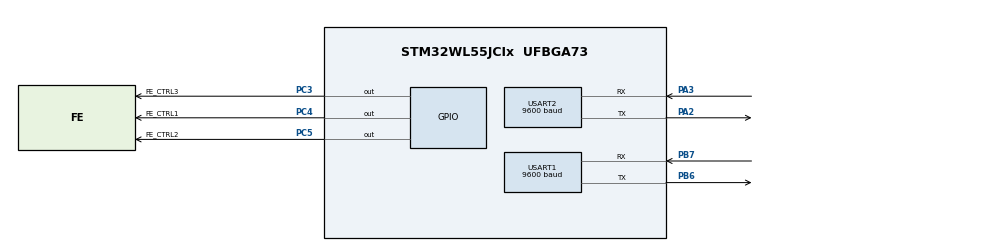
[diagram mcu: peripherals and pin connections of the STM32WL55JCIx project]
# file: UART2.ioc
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Mcu.Family=STM32WL
Mcu.Name=STM32WL55JCIx
Mcu.Package=UFBGA73
NUCLEO-WL55JC1.BUTTON=1
NUCLEO-WL55JC1.BUTTON2=1
NUCLEO-WL55JC1.BUTTON3=1
NUCLEO-WL55JC1.LD1=true
NUCLEO-WL55JC1.LD2=true
NUCLEO-WL55JC1.LD3=true
NUCLEO-WL55JC1.VCP=true
NVIC.EXTI0_IRQn=true\:0\:0\:false\:false\:true\:false\:true\:true
NVIC.EXTI1_IRQn=true\:0\:0\:false\:false\:true\:false\:true\:true
NVIC.EXTI9_5_IRQn=true\:0\:0\:false\:false\:true\:false\:true\:true
NVIC.PriorityGroup=NVIC_PRIORITYGROUP_4
NVIC.RCC_IRQn=true\:0\:0\:false\:false\:true\:true\:false\:true
PA2.Mode=Asynchronous
PA2.Signal=USART2_TX
PA3.Mode=Asynchronous
PA3.Signal=USART2_RX
PB6.Mode=Asynchronous
PB6.Signal=USART1_TX
PB7.Mode=Asynchronous
PB7.Signal=USART1_RX
PC14-OSC32_IN.GPIO_Label=RCC_OSC32_IN
PC14-OSC32_IN.Signal=RCC_OSC32_IN
PC15-OSC32_OUT.GPIO_Label=RCC_OSC32_OUT
PC15-OSC32_OUT.Signal=RCC_OSC32_OUT
PC3.GPIO_Label=FE_CTRL3
PC3.GPIO_Speed=GPIO_SPEED_FREQ_VERY_HIGH
PC3.Signal=GPIO_Output
PC4.GPIO_Label=FE_CTRL1
PC4.GPIO_Speed=GPIO_SPEED_FREQ_VERY_HIGH
PC4.Signal=GPIO_Output
PC5.GPIO_Label=FE_CTRL2
PC5.GPIO_Speed=GPIO_SPEED_FREQ_VERY_HIGH
PC5.Signal=GPIO_Output
ProjectManager.HeapSize=0x200
ProjectManager.StackSize=0x400
ProjectManager.TargetToolchain=STM32CubeIDE
RCC.HSE_VALUE=32000000
RCC.HSI_VALUE=16000000
RCC.LSE_VALUE=32768
RCC.VCOOutputFreq_Value=32000000
USART1.BaudRate=9600
USART1.VirtualMode-Asynchronous=VM_ASYNC
USART2.BaudRate=9600
USART2.VirtualMode-Asynchronous=VM_ASYNC
VP_NUCLEO-WL55JC1_VS_BSP_COMMON.Mode=COMMON
board=NUCLEO-WL55JC1

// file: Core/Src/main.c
/* USER CODE BEGIN Header */
/**
  ******************************************************************************
  * @file           : main.c
  * @brief          : Main program body
  ******************************************************************************
  * @attention
  *
  * Copyright (c) 2026 STMicroelectronics.
  * All rights reserved.
  *
  * This software is licensed under terms that can be found in the LICENSE file
  * in the root directory of this software component.
  * If no LICENSE file comes with this software, it is provided AS-IS.
  *
  ******************************************************************************
  */
/* USER CODE END Header */
#include "main.h"
#include "usart.h"
#include "gpio.h"

/* USER CODE BEGIN Includes */
#include <stdio.h>
#include <string.h>
/* USER CODE END Includes */

COM_InitTypeDef BspCOMInit;

/* USER CODE BEGIN PV */
char display_buffer[4];
uint8_t clear = 0x76;

uint8_t zbk[]={0x3F, 0x06, 0x5B, 0x4F, 0x66, 0x6D, 0x7D, 0x07, 0x7F, 0x67};

/* USER CODE END PV */

void SystemClock_Config(void);

int main(void)
{

  /* MCU Configuration--------------------------------------------------------*/

  /* Reset of all peripherals, Initializes the Flash interface and the Systick. */
  HAL_Init();

  /* Configure the system clock */
  SystemClock_Config();

  /* Initialize all configured peripherals */
  MX_GPIO_Init();
  MX_USART1_UART_Init();
  MX_USART2_UART_Init();

  /* Initialize leds */
  BSP_LED_Init(LED_BLUE);
  BSP_LED_Init(LED_GREEN);
  BSP_LED_Init(LED_RED);

  /* Initialize USER push-button, will be used to trigger an interrupt each time it's pressed.*/
  BSP_PB_Init(BUTTON_SW1, BUTTON_MODE_EXTI);
  BSP_PB_Init(BUTTON_SW2, BUTTON_MODE_EXTI);
  BSP_PB_Init(BUTTON_SW3, BUTTON_MODE_EXTI);

  /* Initialize COM1 port (115200, 8 bits (7-bit data + 1 stop bit), no parity */
  /*
  BspCOMInit.BaudRate   = 9600;
  BspCOMInit.WordLength = COM_WORDLENGTH_8B;
  BspCOMInit.StopBits   = COM_STOPBITS_1;
  BspCOMInit.Parity     = COM_PARITY_NONE;
  BspCOMInit.HwFlowCtl  = COM_HWCONTROL_NONE;
  if (BSP_COM_Init(COM1, &BspCOMInit) != BSP_ERROR_NONE)
  {
    Error_Handler();
  }

  /* Infinite loop */
  /* USER CODE BEGIN WHILE */
  while (1)
  {
      char *msg[5];
      uint8_t clear = 0x76;
	  for (int i = 0; i < 10000; i++)
	  {
		  HAL_UART_Transmit(&huart1, &clear, 1, 100);
		  sprintf(msg, "%4d", i);
	      HAL_UART_Transmit(&huart1, (uint8_t*)msg, 4, 100);
	      HAL_Delay(1000);
	  }
	      BSP_LED_Toggle(LED_BLUE);

	      /* USER CODE END WHILE */
    /* USER CODE END WHILE */

  }
}

void SystemClock_Config(void)
{
  RCC_OscInitTypeDef RCC_OscInitStruct = {0};
  RCC_ClkInitTypeDef RCC_ClkInitStruct = {0};

  /** Configure the main internal regulator output voltage
  */
  __HAL_PWR_VOLTAGESCALING_CONFIG(PWR_REGULATOR_VOLTAGE_SCALE2);

  /** Initializes the CPU, AHB and APB buses clocks
  */
  RCC_OscInitStruct.OscillatorType = RCC_OSCILLATORTYPE_MSI;
  RCC_OscInitStruct.MSIState = RCC_MSI_ON;
  RCC_OscInitStruct.MSICalibrationValue = RCC_MSICALIBRATION_DEFAULT;
  RCC_OscInitStruct.MSIClockRange = RCC_MSIRANGE_6;
  RCC_OscInitStruct.PLL.PLLState = RCC_PLL_NONE;
  if (HAL_RCC_OscConfig(&RCC_OscInitStruct) != HAL_OK)
  {
    Error_Handler();
  }

  /** Configure the SYSCLKSource, HCLK, PCLK1 and PCLK2 clocks dividers
  */
  RCC_ClkInitStruct.ClockType = RCC_CLOCKTYPE_HCLK3|RCC_CLOCKTYPE_HCLK
                              |RCC_CLOCKTYPE_SYSCLK|RCC_CLOCKTYPE_PCLK1
                              |RCC_CLOCKTYPE_PCLK2;
  RCC_ClkInitStruct.SYSCLKSource = RCC_SYSCLKSOURCE_MSI;
  RCC_ClkInitStruct.AHBCLKDivider = RCC_SYSCLK_DIV1;
  RCC_ClkInitStruct.APB1CLKDivider = RCC_HCLK_DIV1;
  RCC_ClkInitStruct.APB2CLKDivider = RCC_HCLK_DIV1;
  RCC_ClkInitStruct.AHBCLK3Divider = RCC_SYSCLK_DIV1;

  if (HAL_RCC_ClockConfig(&RCC_ClkInitStruct, FLASH_LATENCY_0) != HAL_OK)
  {
    Error_Handler();
  }
}

void Error_Handler(void)
{
  __disable_irq();
  while (1)
  {
  }
}
